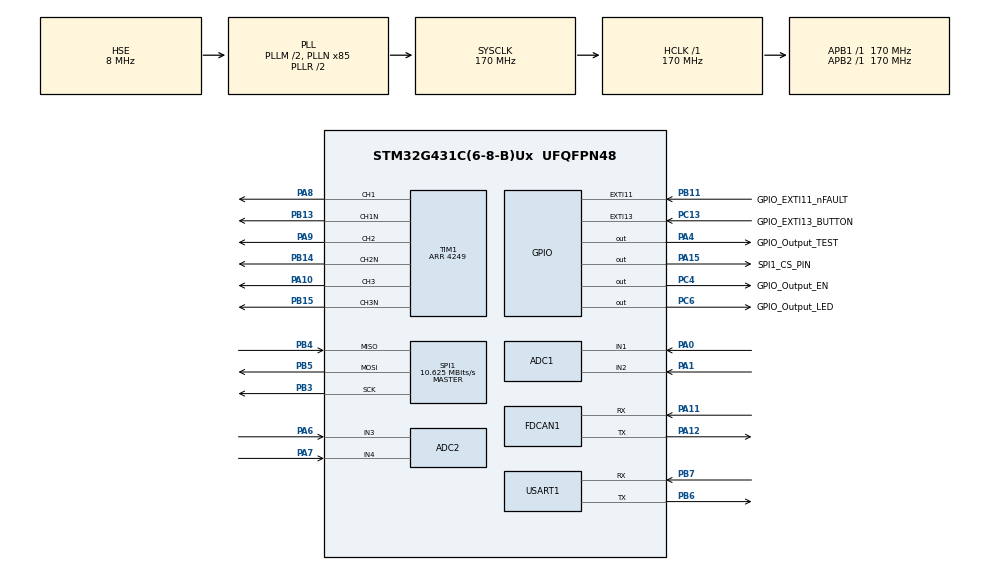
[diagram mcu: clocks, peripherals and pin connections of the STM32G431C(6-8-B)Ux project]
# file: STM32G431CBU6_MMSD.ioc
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ADC1.Channel-0\#ChannelRegularConversion=ADC_CHANNEL_1
ADC1.Channel-1\#ChannelRegularConversion=ADC_CHANNEL_2
ADC1.DMAContinuousRequests=ENABLE
ADC1.ExternalTrigConv=ADC_EXTERNALTRIG_T1_TRGO
ADC1.NbrOfConversion=2
ADC1.NbrOfConversionFlag=1
ADC1.OffsetNumber-0\#ChannelRegularConversion=ADC_OFFSET_NONE
ADC1.OffsetNumber-1\#ChannelRegularConversion=ADC_OFFSET_NONE
ADC1.Rank-0\#ChannelRegularConversion=1
ADC1.Rank-1\#ChannelRegularConversion=2
ADC1.SamplingTime-0\#ChannelRegularConversion=ADC_SAMPLETIME_12CYCLES_5
ADC1.SamplingTime-1\#ChannelRegularConversion=ADC_SAMPLETIME_12CYCLES_5
ADC1.master=1
ADC2.Channel-0\#ChannelRegularConversion=ADC_CHANNEL_3
ADC2.Channel-1\#ChannelRegularConversion=ADC_CHANNEL_4
ADC2.DMAContinuousRequests=ENABLE
ADC2.ExternalTrigConv=ADC_EXTERNALTRIG_T6_TRGO
ADC2.NbrOfConversion=2
ADC2.NbrOfConversionFlag=1
ADC2.OffsetNumber-0\#ChannelRegularConversion=ADC_OFFSET_NONE
ADC2.OffsetNumber-1\#ChannelRegularConversion=ADC_OFFSET_NONE
ADC2.Rank-0\#ChannelRegularConversion=1
ADC2.Rank-1\#ChannelRegularConversion=2
ADC2.SamplingTime-0\#ChannelRegularConversion=ADC_SAMPLETIME_12CYCLES_5
ADC2.SamplingTime-1\#ChannelRegularConversion=ADC_SAMPLETIME_12CYCLES_5
Dma.ADC1.0.Direction=DMA_PERIPH_TO_MEMORY
Dma.ADC1.0.EventEnable=DISABLE
Dma.ADC1.0.Instance=DMA1_Channel1
Dma.ADC1.0.MemDataAlignment=DMA_MDATAALIGN_HALFWORD
Dma.ADC1.0.MemInc=DMA_MINC_ENABLE
Dma.ADC1.0.Mode=DMA_CIRCULAR
Dma.ADC1.0.PeriphDataAlignment=DMA_PDATAALIGN_HALFWORD
Dma.ADC1.0.PeriphInc=DMA_PINC_DISABLE
Dma.ADC1.0.Polarity=HAL_DMAMUX_REQ_GEN_RISING
Dma.ADC1.0.Priority=DMA_PRIORITY_LOW
Dma.ADC1.0.RequestNumber=1
Dma.ADC1.0.SignalID=NONE
Dma.ADC1.0.SyncEnable=DISABLE
Dma.ADC1.0.SyncPolarity=HAL_DMAMUX_SYNC_NO_EVENT
Dma.ADC1.0.SyncRequestNumber=1
Dma.ADC1.0.SyncSignalID=NONE
Dma.ADC2.1.Direction=DMA_PERIPH_TO_MEMORY
Dma.ADC2.1.EventEnable=DISABLE
Dma.ADC2.1.Instance=DMA1_Channel2
Dma.ADC2.1.MemDataAlignment=DMA_MDATAALIGN_HALFWORD
Dma.ADC2.1.MemInc=DMA_MINC_ENABLE
Dma.ADC2.1.Mode=DMA_CIRCULAR
Dma.ADC2.1.PeriphDataAlignment=DMA_PDATAALIGN_HALFWORD
Dma.ADC2.1.PeriphInc=DMA_PINC_DISABLE
Dma.ADC2.1.Polarity=HAL_DMAMUX_REQ_GEN_RISING
Dma.ADC2.1.Priority=DMA_PRIORITY_LOW
Dma.ADC2.1.RequestNumber=1
Dma.ADC2.1.SignalID=NONE
Dma.ADC2.1.SyncEnable=DISABLE
Dma.ADC2.1.SyncPolarity=HAL_DMAMUX_SYNC_NO_EVENT
Dma.ADC2.1.SyncRequestNumber=1
Dma.ADC2.1.SyncSignalID=NONE
Dma.Request0=ADC1
Dma.Request1=ADC2
Dma.Request2=SPI1_RX
Dma.Request3=SPI1_TX
Dma.Request4=USART1_RX
Dma.Request5=USART1_TX
Dma.SPI1_RX.2.Direction=DMA_PERIPH_TO_MEMORY
Dma.SPI1_RX.2.EventEnable=DISABLE
Dma.SPI1_RX.2.Instance=DMA2_Channel1
Dma.SPI1_RX.2.MemDataAlignment=DMA_MDATAALIGN_HALFWORD
Dma.SPI1_RX.2.MemInc=DMA_MINC_ENABLE
Dma.SPI1_RX.2.Mode=DMA_NORMAL
Dma.SPI1_RX.2.PeriphDataAlignment=DMA_PDATAALIGN_HALFWORD
Dma.SPI1_RX.2.PeriphInc=DMA_PINC_DISABLE
Dma.SPI1_RX.2.Polarity=HAL_DMAMUX_REQ_GEN_RISING
Dma.SPI1_RX.2.Priority=DMA_PRIORITY_LOW
Dma.SPI1_RX.2.RequestNumber=1
Dma.SPI1_RX.2.SignalID=NONE
Dma.SPI1_RX.2.SyncEnable=DISABLE
Dma.SPI1_RX.2.SyncPolarity=HAL_DMAMUX_SYNC_NO_EVENT
Dma.SPI1_RX.2.SyncRequestNumber=1
Dma.SPI1_RX.2.SyncSignalID=NONE
Dma.SPI1_TX.3.Direction=DMA_MEMORY_TO_PERIPH
Dma.SPI1_TX.3.EventEnable=DISABLE
Dma.SPI1_TX.3.Instance=DMA2_Channel2
Dma.SPI1_TX.3.MemDataAlignment=DMA_MDATAALIGN_HALFWORD
Dma.SPI1_TX.3.MemInc=DMA_MINC_ENABLE
Dma.SPI1_TX.3.Mode=DMA_NORMAL
Dma.SPI1_TX.3.PeriphDataAlignment=DMA_PDATAALIGN_HALFWORD
Dma.SPI1_TX.3.PeriphInc=DMA_PINC_DISABLE
Dma.SPI1_TX.3.Polarity=HAL_DMAMUX_REQ_GEN_RISING
Dma.SPI1_TX.3.Priority=DMA_PRIORITY_LOW
Dma.SPI1_TX.3.RequestNumber=1
Dma.SPI1_TX.3.SignalID=NONE
Dma.SPI1_TX.3.SyncEnable=DISABLE
Dma.SPI1_TX.3.SyncPolarity=HAL_DMAMUX_SYNC_NO_EVENT
Dma.SPI1_TX.3.SyncRequestNumber=1
Dma.SPI1_TX.3.SyncSignalID=NONE
Dma.USART1_RX.4.Direction=DMA_PERIPH_TO_MEMORY
Dma.USART1_RX.4.EventEnable=DISABLE
Dma.USART1_RX.4.Instance=DMA2_Channel3
Dma.USART1_RX.4.MemDataAlignment=DMA_MDATAALIGN_BYTE
Dma.USART1_RX.4.MemInc=DMA_MINC_ENABLE
Dma.USART1_RX.4.Mode=DMA_NORMAL
Dma.USART1_RX.4.PeriphDataAlignment=DMA_PDATAALIGN_BYTE
Dma.USART1_RX.4.PeriphInc=DMA_PINC_DISABLE
Dma.USART1_RX.4.Polarity=HAL_DMAMUX_REQ_GEN_RISING
Dma.USART1_RX.4.Priority=DMA_PRIORITY_LOW
Dma.USART1_RX.4.RequestNumber=1
Dma.USART1_RX.4.SignalID=NONE
Dma.USART1_RX.4.SyncEnable=DISABLE
Dma.USART1_RX.4.SyncPolarity=HAL_DMAMUX_SYNC_NO_EVENT
Dma.USART1_RX.4.SyncRequestNumber=1
Dma.USART1_RX.4.SyncSignalID=NONE
Dma.USART1_TX.5.Direction=DMA_MEMORY_TO_PERIPH
Dma.USART1_TX.5.EventEnable=DISABLE
Dma.USART1_TX.5.Instance=DMA2_Channel4
Dma.USART1_TX.5.MemDataAlignment=DMA_MDATAALIGN_BYTE
Dma.USART1_TX.5.MemInc=DMA_MINC_ENABLE
Dma.USART1_TX.5.Mode=DMA_NORMAL
Dma.USART1_TX.5.PeriphDataAlignment=DMA_PDATAALIGN_BYTE
Dma.USART1_TX.5.PeriphInc=DMA_PINC_DISABLE
Dma.USART1_TX.5.Polarity=HAL_DMAMUX_REQ_GEN_RISING
Dma.USART1_TX.5.Priority=DMA_PRIORITY_LOW
Dma.USART1_TX.5.RequestNumber=1
Dma.USART1_TX.5.SignalID=NONE
Dma.USART1_TX.5.SyncEnable=DISABLE
Dma.USART1_TX.5.SyncPolarity=HAL_DMAMUX_SYNC_NO_EVENT
Dma.USART1_TX.5.SyncRequestNumber=1
Dma.USART1_TX.5.SyncSignalID=NONE
FDCAN1.CalculateBaudRateNominal=499999
FDCAN1.CalculateTimeBitNominal=2000
FDCAN1.CalculateTimeQuantumNominal=58.82352941176471
FDCAN1.ClockDivider=FDCAN_CLOCK_DIV2
FDCAN1.NominalPrescaler=5
FDCAN1.NominalTimeSeg1=27
FDCAN1.NominalTimeSeg2=6
FDCAN1.StdFiltersNbr=1
Mcu.Family=STM32G4
Mcu.Name=STM32G431C(6-8-B)Ux
Mcu.Package=UFQFPN48
NVIC.DMA1_Channel1_IRQn=true\:4\:0\:true\:false\:true\:false\:true\:true
NVIC.DMA1_Channel2_IRQn=true\:6\:0\:true\:false\:true\:false\:true\:true
NVIC.DMA2_Channel1_IRQn=true\:3\:0\:true\:false\:true\:false\:true\:true
NVIC.DMA2_Channel2_IRQn=true\:3\:0\:true\:false\:true\:false\:true\:true
NVIC.DMA2_Channel3_IRQn=true\:1\:0\:true\:false\:true\:false\:true\:true
NVIC.DMA2_Channel4_IRQn=true\:7\:0\:true\:false\:true\:false\:true\:true
NVIC.EXTI15_10_IRQn=true\:8\:0\:true\:false\:true\:true\:true\:true
NVIC.FDCAN1_IT0_IRQn=true\:6\:0\:true\:false\:true\:true\:true\:true
NVIC.PriorityGroup=NVIC_PRIORITYGROUP_4
NVIC.SPI1_IRQn=true\:3\:0\:true\:false\:true\:true\:true\:true
NVIC.TIM1_UP_TIM16_IRQn=true\:3\:0\:true\:false\:true\:true\:true\:true
NVIC.TIM4_IRQn=true\:10\:0\:true\:false\:true\:true\:true\:true
NVIC.TIM6_DAC_IRQn=true\:6\:0\:true\:false\:true\:true\:true\:true
NVIC.TIM7_IRQn=true\:8\:0\:true\:false\:true\:true\:true\:true
NVIC.USART1_IRQn=true\:1\:0\:true\:false\:true\:true\:true\:true
PA0.Mode=IN1-Single-Ended
PA0.Signal=ADC1_IN1
PA1.Mode=IN2-Single-Ended
PA1.Signal=ADC1_IN2
PA10.Signal=S_TIM1_CH3
PA11.Mode=FDCAN_Activate
PA11.Signal=FDCAN1_RX
PA12.Mode=FDCAN_Activate
PA12.Signal=FDCAN1_TX
PA13.Mode=Serial_Wire
PA13.Signal=SYS_JTMS-SWDIO
PA14.Mode=Serial_Wire
PA14.Signal=SYS_JTCK-SWCLK
PA15.GPIO_Label=SPI1_CS_PIN
PA15.GPIO_PuPd=GPIO_PULLUP
PA15.GPIO_Speed=GPIO_SPEED_FREQ_HIGH
PA15.PinState=GPIO_PIN_SET
PA15.Signal=GPIO_Output
PA4.GPIO_Label=GPIO_Output_TEST
PA4.GPIO_Speed=GPIO_SPEED_FREQ_HIGH
PA4.Signal=GPIO_Output
PA6.Mode=IN3-Single-Ended
PA6.Signal=ADC2_IN3
PA7.Mode=IN4-Single-Ended
PA7.Signal=ADC2_IN4
PA8.Signal=S_TIM1_CH1
PA9.Signal=S_TIM1_CH2
PB11.GPIO_Label=GPIO_EXTI11_nFAULT
PB11.GPIO_ModeDefaultEXTI=GPIO_MODE_IT_FALLING
PB11.Signal=GPXTI11
PB13.Mode=PWM Generation1 CH1 CH1N
PB13.Signal=TIM1_CH1N
PB14.Mode=PWM Generation2 CH2 CH2N
PB14.Signal=TIM1_CH2N
PB15.Mode=PWM Generation3 CH3 CH3N
PB15.Signal=TIM1_CH3N
PB3.Mode=Full_Duplex_Master
PB3.Signal=SPI1_SCK
PB4.Mode=Full_Duplex_Master
PB4.Signal=SPI1_MISO
PB5.Mode=Full_Duplex_Master
PB5.Signal=SPI1_MOSI
PB6.Mode=Asynchronous
PB6.Signal=USART1_TX
PB7.Mode=Asynchronous
PB7.Signal=USART1_RX
PC13.GPIO_Label=GPIO_EXTI13_BUTTON
PC13.Signal=GPXTI13
PC4.GPIO_Label=GPIO_Output_EN
PC4.Signal=GPIO_Output
PC6.GPIO_Label=GPIO_Output_LED
PC6.Signal=GPIO_Output
PF0-OSC_IN.Mode=HSE-External-Oscillator
PF0-OSC_IN.Signal=RCC_OSC_IN
PF1-OSC_OUT.Mode=HSE-External-Oscillator
PF1-OSC_OUT.Signal=RCC_OSC_OUT
ProjectManager.HeapSize=0x200
ProjectManager.StackSize=0x400
ProjectManager.TargetToolchain=CMake
RCC.ADC12Freq_Value=170000000
RCC.AHBFreq_Value=170000000
RCC.APB1Freq_Value=170000000
RCC.APB1TimFreq_Value=170000000
RCC.APB2Freq_Value=170000000
RCC.APB2TimFreq_Value=170000000
RCC.CortexFreq_Value=170000000
RCC.EXTERNAL_CLOCK_VALUE=12288000
RCC.EnbaleCSS=true
RCC.HCLKFreq_Value=170000000
RCC.HSE_VALUE=8000000
RCC.HSI48_VALUE=48000000
RCC.HSI_VALUE=16000000
RCC.LSE_VALUE=32768
RCC.PLLM=RCC_PLLM_DIV2
RCC.PLLN=85
RCC.PLLSourceVirtual=RCC_PLLSOURCE_HSE
RCC.SYSCLKFreq_VALUE=170000000
RCC.SYSCLKSource=RCC_SYSCLKSOURCE_PLLCLK
RCC.USBFreq_Value=170000000
RCC.VCOOutputFreq_Value=340000000
SH.S_TIM1_CH1.0=TIM1_CH1,PWM Generation1 CH1 CH1N
SH.S_TIM1_CH2.0=TIM1_CH2,PWM Generation2 CH2 CH2N
SH.S_TIM1_CH3.0=TIM1_CH3,PWM Generation3 CH3 CH3N
SPI1.BaudRatePrescaler=SPI_BAUDRATEPRESCALER_16
SPI1.CLKPhase=SPI_PHASE_2EDGE
SPI1.CalculateBaudRate=10.625 MBits/s
SPI1.DataSize=SPI_DATASIZE_16BIT
SPI1.Direction=SPI_DIRECTION_2LINES
SPI1.Mode=SPI_MODE_MASTER
SPI1.VirtualType=VM_MASTER
STMicroelectronics.X-CUBE-ALGOBUILD.1.5.0.LibraryCcDSPOoLibraryJjDSPOoLibrary=true
TIM1.AutoReloadPreload=TIM_AUTORELOAD_PRELOAD_ENABLE
TIM1.Channel-PWM\ Generation1\ CH1\ CH1N=TIM_CHANNEL_1
TIM1.Channel-PWM\ Generation2\ CH2\ CH2N=TIM_CHANNEL_2
TIM1.Channel-PWM\ Generation3\ CH3\ CH3N=TIM_CHANNEL_3
TIM1.CounterMode=TIM_COUNTERMODE_CENTERALIGNED1
TIM1.DeadTime=34
TIM1.PeriodNoDither=4249
TIM1.RepetitionCounter=1
TIM1.TIM_MasterOutputTrigger=TIM_TRGO_UPDATE
TIM4.AutoReloadPreload=TIM_AUTORELOAD_PRELOAD_ENABLE
TIM4.PeriodNoDither=19999
TIM4.Prescaler=169
TIM6.AutoReloadPreload=TIM_AUTORELOAD_PRELOAD_ENABLE
TIM6.PeriodNoDither=999
TIM6.Prescaler=169
TIM6.TIM_MasterOutputTrigger=TIM_TRGO_UPDATE
TIM7.AutoReloadPreload=TIM_AUTORELOAD_PRELOAD_ENABLE
TIM7.PeriodNoDither=9999
TIM7.Prescaler=169
TIM7.TIM_MasterOutputTrigger=TIM_TRGO_UPDATE
USART1.VirtualMode-Asynchronous=VM_ASYNC
VP_STMicroelectronics.X-CUBE-ALGOBUILD_VS_DSPOoLibraryJjLibrary_1.5.0_1.5.0.Mode=DSPOoLibraryJjLibrary
VP_SYS_VS_DBSignals.Mode=DisableDeadBatterySignals
VP_TIM1_VS_ClockSourceINT.Mode=Internal
VP_TIM4_VS_ClockSourceINT.Mode=Internal
VP_TIM6_VS_ClockSourceINT.Mode=Enable_Timer
VP_TIM7_VS_ClockSourceINT.Mode=Enable_Timer
board=custom

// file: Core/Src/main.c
/* USER CODE BEGIN Header */
/**
  ******************************************************************************
  * @file           : main.c
  * @brief          : Main program body
  ******************************************************************************
  * @attention
  *
  * Copyright (c) 2026 STMicroelectronics.
  * All rights reserved.
  *
  * This software is licensed under terms that can be found in the LICENSE file
  * in the root directory of this software component.
  * If no LICENSE file comes with this software, it is provided AS-IS.
  *
  ******************************************************************************
  */
/* USER CODE END Header */
#include "main.h"
#include "adc.h"
#include "dma.h"
#include "fdcan.h"
#include "spi.h"
#include "tim.h"
#include "usart.h"
#include "gpio.h"

/* USER CODE BEGIN Includes */
#include "app_foc.h"
/* USER CODE END Includes */

void SystemClock_Config(void);

int main(void)
{

  /* MCU Configuration--------------------------------------------------------*/

  /* Reset of all peripherals, Initializes the Flash interface and the Systick. */
  HAL_Init();

  /* Configure the system clock */
  SystemClock_Config();

  /* Initialize all configured peripherals */
  MX_GPIO_Init();
  MX_DMA_Init();
  MX_ADC1_Init();
  MX_ADC2_Init();
  MX_FDCAN1_Init();
  MX_SPI1_Init();
  MX_TIM1_Init();
  MX_USART1_UART_Init();
  MX_TIM6_Init();
  MX_TIM7_Init();
  MX_TIM4_Init();
  /* USER CODE BEGIN 2 */

  /* 应用层初始化（FOC 系统 + 控制模式） */
  App_Init();

  /* USER CODE END 2 */

  /* Infinite loop */
  while (1)
  {

    /* 应用层主循环任务（LED 心跳 + 故障恢复 + 在线调参 + 控制模式） */
    App_Run();

  }
}

void SystemClock_Config(void)
{
  RCC_OscInitTypeDef RCC_OscInitStruct = {0};
  RCC_ClkInitTypeDef RCC_ClkInitStruct = {0};

  /** Configure the main internal regulator output voltage
  */
  HAL_PWREx_ControlVoltageScaling(PWR_REGULATOR_VOLTAGE_SCALE1_BOOST);

  /** Initializes the RCC Oscillators according to the specified parameters
  * in the RCC_OscInitTypeDef structure.
  */
  RCC_OscInitStruct.OscillatorType = RCC_OSCILLATORTYPE_HSE;
  RCC_OscInitStruct.HSEState = RCC_HSE_ON;
  RCC_OscInitStruct.PLL.PLLState = RCC_PLL_ON;
  RCC_OscInitStruct.PLL.PLLSource = RCC_PLLSOURCE_HSE;
  RCC_OscInitStruct.PLL.PLLM = RCC_PLLM_DIV2;
  RCC_OscInitStruct.PLL.PLLN = 85;
  RCC_OscInitStruct.PLL.PLLP = RCC_PLLP_DIV2;
  RCC_OscInitStruct.PLL.PLLQ = RCC_PLLQ_DIV2;
  RCC_OscInitStruct.PLL.PLLR = RCC_PLLR_DIV2;
  if (HAL_RCC_OscConfig(&RCC_OscInitStruct) != HAL_OK)
  {
    Error_Handler();
  }

  /** Initializes the CPU, AHB and APB buses clocks
  */
  RCC_ClkInitStruct.ClockType = RCC_CLOCKTYPE_HCLK|RCC_CLOCKTYPE_SYSCLK
                              |RCC_CLOCKTYPE_PCLK1|RCC_CLOCKTYPE_PCLK2;
  RCC_ClkInitStruct.SYSCLKSource = RCC_SYSCLKSOURCE_PLLCLK;
  RCC_ClkInitStruct.AHBCLKDivider = RCC_SYSCLK_DIV1;
  RCC_ClkInitStruct.APB1CLKDivider = RCC_HCLK_DIV1;
  RCC_ClkInitStruct.APB2CLKDivider = RCC_HCLK_DIV1;

  if (HAL_RCC_ClockConfig(&RCC_ClkInitStruct, FLASH_LATENCY_4) != HAL_OK)
  {
    Error_Handler();
  }

  /** Enables the Clock Security System
  */
  HAL_RCC_EnableCSS();
}

void Error_Handler(void)
{
  __disable_irq();
  while (1)
  {
  }
}
